# SIM3U166_B register map
File version: 1
CPU: 
Registers are 32-bit, read-write, reset 0x0 unless marked. A register's access mark holds for its fields unless they carry their own. Offsets are from the block's base; [hi:lo] are bit positions.

## LOCK_0
Base 0x40049000
0x00 KEY — Security Key
  [7:0] KEY — Peripheral Lock Mask Key.
    0=LOCKED (PERIPHLOCK registers are locked and no valid values have been written to KEY.); 1=INTERMEDIATE (PERIPHLOCK registers are locked and the first valid value (0xA5) has been written to KEY.); 2=UNLOCKED (PERIPHLOCK registers are unlocked. Any subsequent writes to KEY will lock the interface.)
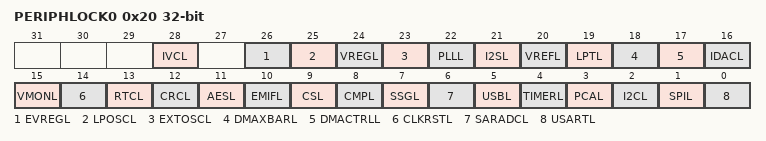
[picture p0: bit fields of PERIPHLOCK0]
0x20 PERIPHLOCK0 — Peripheral Lock Control 0
  [28] IVCL — IVC Module Lock Enable.
    0=UNLOCKED (Unlock the IVC0 Module registers.); 1=LOCKED (Lock the IVC0 Module registers (bits can still be read).)
  [26] EVREGL — External Regulator Module Lock Enable.
    0=UNLOCKED (Unlock the External Regulator (EXTVREG0) Module registers.); 1=LOCKED (Lock the External Regulator (EXTVREG0) Module registers (bits can still be read).)
  [25] LPOSCL — Low Power Oscillator Lock Enable.
    0=UNLOCKED (Unlock the Low Power Oscillator (LPOSC0) Module registers.); 1=LOCKED (Lock the Low Power Oscillator (LPOSC0) Module registers (bits can still be read).)
  [24] VREGL — Voltage Regulator Module Lock Enable.
    0=UNLOCKED (Unlock the Voltage Regulator (VREG0) Module registers.); 1=LOCKED (Lock the Voltage Regulator (VREG0) Module registers (bits can still be read).)
  [23] EXTOSCL — External Oscillator Module Lock Enable.
    0=UNLOCKED (Unlock the External Oscillator (EXTOSC0) Module registers.); 1=LOCKED (Lock the External Oscillator (EXTOSC0) Module registers (bits can still be read).)
  [22] PLLL — PLL Module Lock Enable.
    0=UNLOCKED (Unlock the PLL0 Module registers.); 1=LOCKED (Lock the PLL0 Module registers (bits can still be read).)
  [21] I2SL — I2S Module Lock Enable.
    0=UNLOCKED (Unlock the I2S0 Module registers.); 1=LOCKED (Lock the I2S0 Module registers (bits can still be read).)
  [20] VREFL — Voltage Reference Module Lock Enable.
    0=UNLOCKED (Unlock the Voltage Reference (VREF0) Module registers.); 1=LOCKED (Lock the Voltage Reference (VREF0) Module registers (bits can still be read).)
  [19] LPTL — Low Power Timer Module Lock Enable.
    0=UNLOCKED (Unlock the Low Power Timer (LPTIMER0) Module registers.); 1=LOCKED (Lock the Low Power Timer (LPTIMER0) Module registers (bits can still be read).)
  [18] DMAXBARL — DMA Crossbar Module Lock Enable.
    0=UNLOCKED (Unlock the DMA Crossbar (DMAXBAR0) Module registers.); 1=LOCKED (Lock the DMA Crossbar (DMAXBAR0) Module registers (bits can still be read).)
  [17] DMACTRLL — DMA Controller Module Lock Enable.
    0=UNLOCKED (Unlock the DMA Controller (DMACTRL0) Module registers.); 1=LOCKED (Lock the DMA Controller (DMACTRL0) Module registers (bits can still be read).)
  [16] IDACL — IDAC Module Lock Enable.
    0=UNLOCKED (Unlock the IDAC0 and IDAC1 Module registers.); 1=LOCKED (Lock the IDAC0 and IDAC1 Module registers (bits can still be read).)
  [15] VMONL — Voltage Supply Monitor Module Lock Enable.
    0=UNLOCKED (Unlock the Voltage Supply Monitor (VMON0) Module registers.); 1=LOCKED (Lock the Voltage Supply Monitor (VMON0) Module registers (bits can still be read).)
  [14] CLKRSTL — Clock Control and Reset Sources Lock Enable.
    0=UNLOCKED (Unlock the Clock Control (CLKCTRL) and Reset Sources (RSTSRC) Module registers.); 1=LOCKED (Lock the Clock Control (CLKCTRL) and Reset Sources (RSTSRC) Module registers (bits can still be read).)
  [13] RTCL — RTC Module Lock Enable.
    0=UNLOCKED (Unlock the RTC0 Module registers.); 1=LOCKED (Lock the RTC0 Module registers (bits can still be read).)
  [12] CRCL — CRC Module Lock Enable.
    0=UNLOCKED (Unlock the CRC0 Module registers.); 1=LOCKED (Lock the CRC0 Module registers (bits can still be read).)
  [11] AESL — AES Module Lock Enable.
    0=UNLOCKED (Unlock the AES0 Module registers.); 1=LOCKED (Lock the AES0 Module registers (bits can still be read).)
  [10] EMIFL — EMIF Module Lock Enable.
    0=UNLOCKED (Unlock the External Memory Interface (EMIF0) Module registers.); 1=LOCKED (Lock the External Memory Interface (EMIF0) Module registers (bits can still be read).)
  [9] CSL — Capacitive Sensing Module Lock Enable.
    0=UNLOCKED (Unlock the Capacitive Sensing (CAPSENSE0) Module registers.); 1=LOCKED (Lock the Capacitive Sensing (CAPSENSE0) Module registers (bits can still be read).)
  [8] CMPL — Comparator Module Lock Enable.
    0=UNLOCKED (Unlock the Comparator 0 and Comparator 1 Module registers.); 1=LOCKED (Lock the Comparator 0 and Comparator 1 Module registers (bits can still be read).)
  [7] SSGL — SSG Module Lock Enable.
    0=UNLOCKED (Unlock the SSG0 Module registers.); 1=LOCKED (Lock the SSG0 Module registers (bits can still be read).)
  [6] SARADCL — SARADC Module Lock Enable.
    0=UNLOCKED (Unlock the SARADC0 and SARADC1 Module registers.); 1=LOCKED (Lock the SARADC0 and SARADC1 Module registers (bits can still be read).)
  [5] USBL — USB Module Lock Enable.
    0=UNLOCKED (Unlock the USB0 Module registers.); 1=LOCKED (Lock the USB0 Module registers (bits can still be read).)
  [4] TIMERL — Timer Module Lock Enable.
    0=UNLOCKED (Unlock the TIMER0 and TIMER1 Module registers.); 1=LOCKED (Lock the TIMER0 and TIMER1 Module registers (bits can still be read).)
  [3] PCAL — PCA Module Lock Enable.
    0=UNLOCKED (Unlock the EPCA0, PCA0, and PCA1 Module registers.); 1=LOCKED (Lock the EPCA0, PCA0, and PCA1 Module registers (bits can still be read).)
  [2] I2CL — I2C Module Lock Enable.
    0=UNLOCKED (Unlock the I2C0 and I2C1 Module registers.); 1=LOCKED (Lock the I2C0 and I2C1 Module registers (bits can still be read).)
  [1] SPIL — SPI Module Lock Enable.
    0=UNLOCKED (Unlock the SPI0, SPI1, and SPI2 Module registers.); 1=LOCKED (Lock the SPI0, SPI1, and SPI2 Module registers (bits can still be read).)
  [0] USARTL — USART/UART Module Lock Enable.
    0=UNLOCKED (Unlock the USART0, USART1, UART0, and UART1 Module registers.); 1=LOCKED (Lock the USART0, USART1, UART0, and UART1 Module registers (bits can still be read).)
0x40 PERIPHLOCK1 — Peripheral Lock Control 1
  [0] PMUL — PMU Module Lock Enable.
    0=UNLOCKED (Unlock the PMU Module registers.); 1=LOCKED (Lock the PMU Module registers (bits can still be read).)
